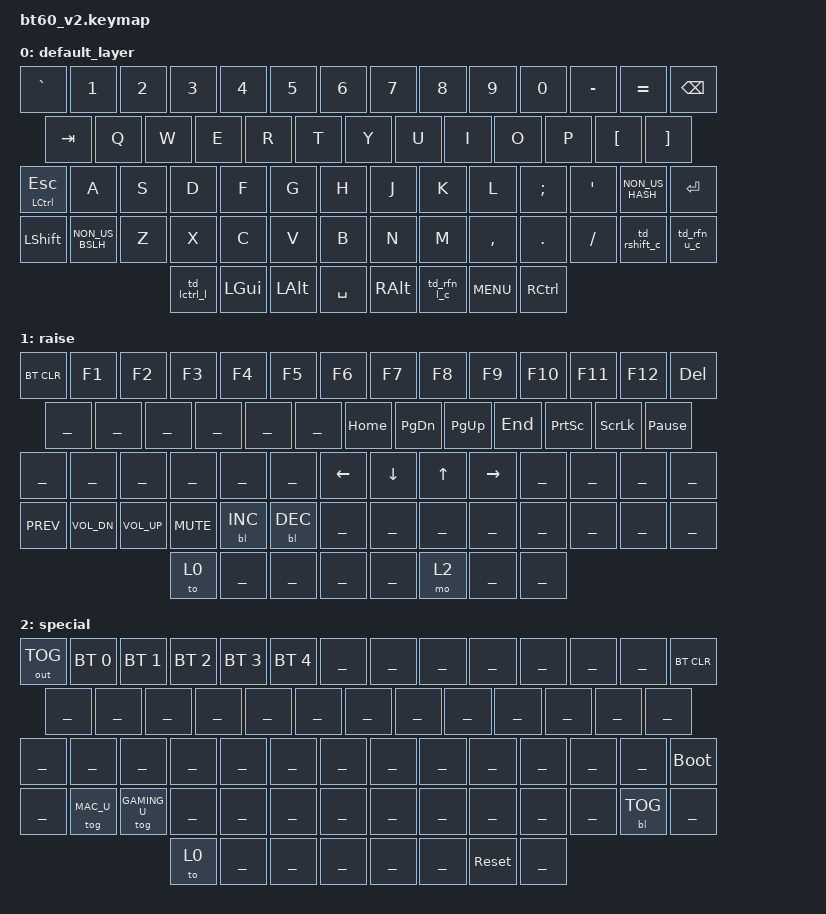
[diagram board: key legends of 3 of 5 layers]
#include <behaviors.dtsi>
#include <dt-bindings/zmk/keys.h>
#include <dt-bindings/zmk/bt.h>
#include <dt-bindings/zmk/rgb.h>
#include <dt-bindings/zmk/backlight.h>
#include <dt-bindings/zmk/outputs.h>

#define K_E 17
#define K_O 23
#define K_A 28

#include "utils/common.h"

#define DEFAULT 0
#define RAISE   1
#define SPECIAL 2
#define MAC_U   3
#define GAMING_U 4

COMBO(lnx_oe_comb, K_O K_E, DEFAULT, &lnx_no_oe)
COMBO(lnx_ae_comb, K_A K_E, DEFAULT, &lnx_no_ae)
COMBO(lnx_ao_comb, K_A K_O, DEFAULT, &lnx_no_ao)
COMBO(mwn_oe_comb, 54 37, MAC_U, &mwn_no_oe)
COMBO(mwn_ae_comb, 54 38, MAC_U, &mwn_no_ae)
COMBO(mwn_ao_comb, 54 25, MAC_U, &mwn_no_ao)

/ {
    behaviors {
        mo_tog: behavior_mo_tog {
            compatible = "zmk,behavior-hold-tap";
            label = "mo_tog";
            #binding-cells = <2>;
            flavor = "hold-preferred";
            tapping-term-ms = <200>;
            bindings = <&mo>, <&tog>;
        };
        td_rfn_u_c: rfn_u {
            compatible = "zmk,behavior-tap-dance";
            label = "RFN_UPPER";
            #binding-cells = <0>;
            tapping-term-ms = <200>;
            bindings = <&mo 1>, <&tog 1>;
        };
        td_rfn_l_c: rfn_l {
            compatible = "zmk,behavior-tap-dance";
            label = "RFN_LOWER";
            #binding-cells = <0>;
            tapping-term-ms = <200>;
            bindings = <&mo 1>, <&mo 2>;
        };
        td_lctrl_l: lctrl_l {
            compatible = "zmk,behavior-tap-dance";
            label = "LCTRL_LOWER";
            #binding-cells = <0>;
            tapping-term-ms = <200>;
            bindings = <&mo 1>, <&mo 2>;
        };
        td_lshift_c: lshift_caps {
            compatible = "zmk,behavior-tap-dance";
            label = "LSHIFT_CAPS";
            #binding-cells = <0>;
            tapping-term-ms = <200>;
            bindings = <&kp LSHFT>, <&kp CAPS>;
        };
        td_rshift_c: rshift_caps {
            compatible = "zmk,behavior-tap-dance";
            label = "RSHIFT_CAPS";
            #binding-cells = <0>;
            tapping-term-ms = <200>;
            bindings = <&kp RSHFT>, <&kp CAPS>;
        };
    };

	keymap {
		compatible = "zmk,keymap";

		default_layer {
				// ------------------------------------------------------------------------------------------
				// |  `  |  1  |  2  |  3  |  4  |  5  |  6  |  7  |  8  |  9  |  0  |  -  |  =  |   BKSP
				// | TAB  |  Q  |  W  |  E  |  R  |  T  |  Y  |  U  |  I  |  O  |  P  |  [  |  ]  |        |
				// | CAPS  |  A  |  S  |  D  |  F  |  G  |  H  |  J  |  K  |  L  |  ;  |  '  |  #  | ENTER |
				// |  SHIFT|  \ |  Z  | trans  |  .  | /   |    SHIFT    |
				// |  CTL  |  WIN  |  ALT  |            SPACE               | ALT | 1    |  MENU    |  CTRL|
				// ------------------------------------------------------------------------------------------
			bindings = <

				&kp GRAVE &kp N1 &kp N2 &kp N3 &kp N4 &kp N5 &kp N6 &kp N7 &kp  N8   &kp  N9 &kp  N0  &kp MINUS &kp EQUAL &kp BSPC
				&kp TAB   &kp Q  &kp W  &kp E  &kp R  &kp T  &kp Y  &kp U  &kp  I    &kp  O  &kp  P   &kp LBKT &kp RBKT
				&mt LCTRL ESC   &kp A  &kp S  &kp D  &kp F  &kp G  &kp H  &kp J  &kp K &kp L &kp SEMI &kp SQT &kp NON_US_HASH  &kp RET
				&kp LSHIFT &kp NON_US_BSLH &kp Z  &kp X  &kp C  &kp V  &kp B  &kp N  &kp M  &kp COMMA &kp DOT &kp FSLH         &td_rshift_c &td_rfn_u_c
				&td_lctrl_l &kp LGUI &kp LALT            &kp SPACE                          &kp RALT  &td_rfn_l_c &kp C_MENU    &kp RCTRL
			>;
			sensor-bindings = <&inc_dec_kp C_VOL_UP C_VOL_DN>;
		};
		raise {
			bindings = <
				&bt BT_CLR &kp F1 &kp F2 &kp F3 &kp F4 &kp F5 &kp F6 &kp F7 &kp F8 &kp F9 &kp F10 &kp F11 &kp F12 &kp DEL
				___ ___ ___ ___ ___ ___ &kp HOME &kp PG_DN &kp PG_UP &kp END &kp PSCRN &kp SLCK &kp PAUSE_BREAK
				___ ___ ___ ___ ___ ___ &kp LEFT &kp DOWN &kp UP &kp RIGHT ___ ___ ___ ___
				&kp C_PREV &kp C_VOL_DN &kp C_VOL_UP &kp C_MUTE &bl BL_INC &bl BL_DEC ___ ___ ___ ___ ___ ___  ___ ___
				&to 0 ___  ___              ___                            ___   &mo 2   ___ ___
			>;
			sensor-bindings = <&inc_dec_kp C_VOL_UP C_VOL_DN>;
		};
		special {
			bindings = <
				&out OUT_TOG &bt BT_SEL 0 &bt BT_SEL 1 &bt BT_SEL 2 &bt BT_SEL 3 &bt BT_SEL 4 ___ ___ ___ ___ ___ ___ ___ &bt BT_CLR
				___ ___ ___ ___ ___ ___ ___ ___ ___ ___ ___ ___ ___
				___ ___ ___ ___ ___ ___ ___ ___ ___ ___ ___ ___ ___ &bootloader
				___ &tog MAC_U &tog GAMING_U ___ ___ ___ ___ ___ ___ ___ ___ ___  &bl BL_TOG ___
				&to 0 ___  ___              ___                            ___   ___   &sys_reset ___
			>;
			sensor-bindings = <&inc_dec_kp C_VOL_UP C_VOL_DN>;
		};


		mac_unicode {
			bindings = <
				___ ___ ___ ___ ___ ___ ___ ___ ___ ___ ___ ___ ___ ___
				___ ___ ___ ___ ___ ___ ___ ___ ___ ___ ___ ___ ___
				___ ___ ___ ___ ___ ___ ___ ___ ___ ___ ___ ___ ___ ___
				___ ___ ___ ___ ___ ___ ___ ___ ___ ___ ___ ___  ___
				___ ___  ___              ___              ___   ___  ___ ___
			>;
			sensor-bindings = <&inc_dec_kp C_VOL_UP C_VOL_DN>;
		};
		gaming {
			bindings = <
				&kp ESC    ___ ___ ___ ___ ___ ___ ___ ___ ___ ___ ___ ___ ___
				___        ___ &kp W ___ ___ ___ ___ ___ ___ ___ ___ ___ ___
				&kp LCTRL  &kp A &kp S &kp D &kp F ___ ___ &kp J &kp K &kp L &kp SEMI ___ ___ ___
				&kp LSHIFT ___ ___ ___ ___ ___ ___ ___ ___ ___ ___ ___  ___
				&kp LCTRL  ___  ___              ___              ___   ___  ___ ___
			>;
			sensor-bindings = <&inc_dec_kp C_VOL_UP C_VOL_DN>;
		};

	};
};

